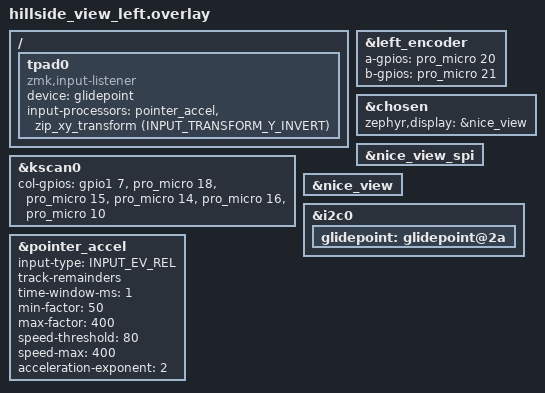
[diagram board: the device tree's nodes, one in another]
/*
 * Copyright (c) 2022 The ZMK Contributors
 *
 * SPDX-License-Identifier: MIT
 */

#include "hillside_view.dtsi"
#include <input/processors.dtsi>
#include <behaviors/input_gestures_accel.dtsi>

// to translate absolute positions to relative positions. If you don't
// want to use gestures for absolute mode, and you don't want to activate it,
// you can ignore this line

&kscan0  {
    col-gpios
        = <&gpio1 7 GPIO_ACTIVE_HIGH>
        , <&pro_micro 18 GPIO_ACTIVE_HIGH>
        , <&pro_micro 15 GPIO_ACTIVE_HIGH>
        , <&pro_micro 14 GPIO_ACTIVE_HIGH>
        , <&pro_micro 16 GPIO_ACTIVE_HIGH>
        , <&pro_micro 10 GPIO_ACTIVE_HIGH>
        ;
};

&left_encoder {
    status = "okay";
  a-gpios = <&pro_micro 20 (GPIO_ACTIVE_HIGH | GPIO_PULL_UP)>;
  b-gpios = <&pro_micro 21 (GPIO_ACTIVE_HIGH | GPIO_PULL_UP)>;
};

&chosen {
  zephyr,display = &nice_view;
};

// nice view bus
&nice_view_spi {
  status = "okay";
};

&nice_view {
  status = "okay";
};

&i2c0 {
    status = "okay";
    glidepoint: glidepoint@2a {
        status = "okay";
    };
};

&pointer_accel {
    input-type = <INPUT_EV_REL>;
    track-remainders;
    time-window-ms = <1>;  // 1ms = 1000Hz, matches common wired rate
    min-factor = <50>;        // 0.5x at very slow speeds
    max-factor = <400>;       // 4.0x at fast speeds
    speed-threshold = <80>;   // 800 counts/sec for 1x
    speed-max = <400>;        // 4000 counts/sec for maximum acceleration
    acceleration-exponent = <2>; // quadratic curve
};

/ {
  tpad0: tpad0 {
        compatible = "zmk,input-listener";
        status = "okay";
        device = <&glidepoint>;
        input-processors = <
            &pointer_accel
            &zip_xy_transform (INPUT_TRANSFORM_Y_INVERT)
            >;
    };
};
